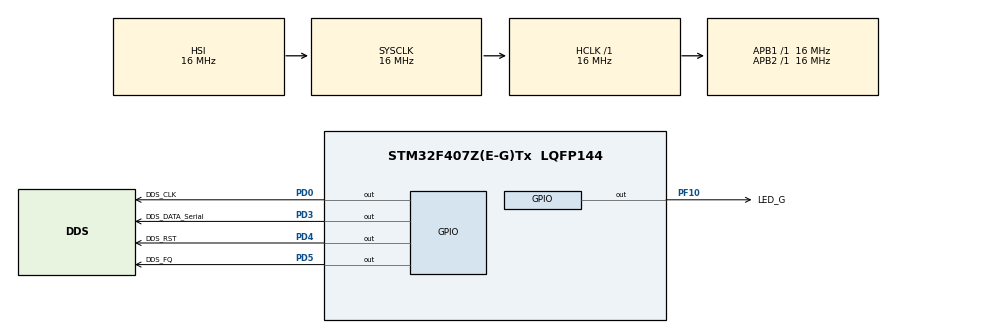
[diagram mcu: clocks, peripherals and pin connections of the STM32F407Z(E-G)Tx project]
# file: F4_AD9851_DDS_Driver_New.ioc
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Mcu.Family=STM32F4
Mcu.Name=STM32F407Z(E-G)Tx
Mcu.Package=LQFP144
NVIC.PriorityGroup=NVIC_PRIORITYGROUP_4
PA13.Mode=Serial_Wire
PA13.Signal=SYS_JTMS-SWDIO
PA14.Mode=Serial_Wire
PA14.Signal=SYS_JTCK-SWCLK
PD0.GPIO_Label=DDS_CLK
PD0.GPIO_Speed=GPIO_SPEED_FREQ_HIGH
PD0.Signal=GPIO_Output
PD3.GPIO_Label=DDS_DATA_Serial
PD3.GPIO_Speed=GPIO_SPEED_FREQ_HIGH
PD3.Signal=GPIO_Output
PD4.GPIO_Label=DDS_RST
PD4.GPIO_Speed=GPIO_SPEED_FREQ_HIGH
PD4.Signal=GPIO_Output
PD5.GPIO_Label=DDS_FQ
PD5.GPIO_Speed=GPIO_SPEED_FREQ_HIGH
PD5.PinState=GPIO_PIN_RESET
PD5.Signal=GPIO_Output
PF10.GPIO_Label=LED_G
PF10.Signal=GPIO_Output
PH0-OSC_IN.Mode=HSE-External-Oscillator
PH0-OSC_IN.Signal=RCC_OSC_IN
PH1-OSC_OUT.Mode=HSE-External-Oscillator
PH1-OSC_OUT.Signal=RCC_OSC_OUT
ProjectManager.HeapSize=0x200
ProjectManager.StackSize=0x400
ProjectManager.TargetToolchain=MDK-ARM V5.32
RCC.AHBFreq_Value=16000000
RCC.APB1Freq_Value=16000000
RCC.APB2Freq_Value=16000000
RCC.CortexFreq_Value=16000000
RCC.HSE_VALUE=25000000
RCC.HSI_VALUE=16000000
RCC.LSE_VALUE=32768
RCC.SYSCLKFreq_VALUE=16000000
RCC.VCOOutputFreq_Value=192000000
board=custom

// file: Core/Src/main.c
/* USER CODE BEGIN Header */
#include "AD985x.h"
/**
  ******************************************************************************
  * @file           : main.c
  * @brief          : Main program body
  ******************************************************************************
  * @attention
  *
  * Copyright (c) 2023 STMicroelectronics.
  * All rights reserved.
  *
  * This software is licensed under terms that can be found in the LICENSE file
  * in the root directory of this software component.
  * If no LICENSE file comes with this software, it is provided AS-IS.
  *
  ******************************************************************************
  */
/* USER CODE END Header */
#include "main.h"
#include "gpio.h"

void SystemClock_Config(void);

int main(void)
{

  /* MCU Configuration--------------------------------------------------------*/

  /* Reset of all peripherals, Initializes the Flash interface and the Systick. */
  HAL_Init();

  /* Configure the system clock */
  SystemClock_Config();

  /* Initialize all configured peripherals */
  MX_GPIO_Init();
  /* USER CODE BEGIN 2 */

  // 代码移植建议
  // 1.修改头文件AD985x.h中，自己控制板实际需要使用哪些控制引脚。如AD985x_rst脚改成PA0控制，则定义"#define AD985x_rst	PAout(0)"
  // 2.修改C文件AD985x.c中，AD985x_IO_Init函数，所有用到管脚的GPIO输出功能初始化
  // 3.完成

  HAL_Delay(1000);  // 延迟，确保 AD9851 上电完成

  //	AD985x_Init(AD9850,PARALLEL);		//初始化控制AD9850需要用到的IO口,设置为并行通讯
  //	AD985x_Init(AD9850,SERIAL);		//初始化控制AD9850需要用到的IO口,设置为串行通讯
  //	AD985x_Init(AD9851,PARALLEL);		//初始化控制AD9851需要用到的IO口,设置为并行通讯
  AD985x_Init(AD9851, SERIAL); // 初始化控制AD9851需要用到的IO口,设置为串行通讯
  // 程序兼容AD9850和AD9851模块及串并行通讯；填入不同参数初始化即可

  AD985x_SetFre_Phase(14.3E6, 8); // 设置输出频率1000Hz,相位90度

  /* USER CODE END 2 */

  /* Infinite loop */
  while (1)
  {

    /* USER CODE BEGIN 3 */
    HAL_Delay(1000);
    HAL_GPIO_TogglePin(LED_G_GPIO_Port, LED_G_Pin);
  }
  /* USER CODE END 3 */
}

void SystemClock_Config(void)
{
  RCC_OscInitTypeDef RCC_OscInitStruct = {0};
  RCC_ClkInitTypeDef RCC_ClkInitStruct = {0};

  /** Configure the main internal regulator output voltage
  */
  __HAL_RCC_PWR_CLK_ENABLE();
  __HAL_PWR_VOLTAGESCALING_CONFIG(PWR_REGULATOR_VOLTAGE_SCALE1);

  /** Initializes the RCC Oscillators according to the specified parameters
  * in the RCC_OscInitTypeDef structure.
  */
  RCC_OscInitStruct.OscillatorType = RCC_OSCILLATORTYPE_HSI;
  RCC_OscInitStruct.HSIState = RCC_HSI_ON;
  RCC_OscInitStruct.HSICalibrationValue = RCC_HSICALIBRATION_DEFAULT;
  RCC_OscInitStruct.PLL.PLLState = RCC_PLL_NONE;
  if (HAL_RCC_OscConfig(&RCC_OscInitStruct) != HAL_OK)
  {
    Error_Handler();
  }

  /** Initializes the CPU, AHB and APB buses clocks
  */
  RCC_ClkInitStruct.ClockType = RCC_CLOCKTYPE_HCLK|RCC_CLOCKTYPE_SYSCLK
                              |RCC_CLOCKTYPE_PCLK1|RCC_CLOCKTYPE_PCLK2;
  RCC_ClkInitStruct.SYSCLKSource = RCC_SYSCLKSOURCE_HSI;
  RCC_ClkInitStruct.AHBCLKDivider = RCC_SYSCLK_DIV1;
  RCC_ClkInitStruct.APB1CLKDivider = RCC_HCLK_DIV1;
  RCC_ClkInitStruct.APB2CLKDivider = RCC_HCLK_DIV1;

  if (HAL_RCC_ClockConfig(&RCC_ClkInitStruct, FLASH_LATENCY_0) != HAL_OK)
  {
    Error_Handler();
  }
}

void Error_Handler(void)
{
  __disable_irq();
  while (1)
  {
  }
}
